# STM32MP23_CM33 register map
File version: 1.2
CPU: CM33 r0p1, little endian, MPU, FPU, vendor SysTick, 8 interrupt priority bits
Registers are 32-bit, read-write, reset 0x0 unless marked. A register's access mark holds for its fields unless they carry their own. Offsets are from the block's base; [hi:lo] are bit positions; {n}, {i} and the like mark numbered series.

## DSI (part 1 of 2) — DSI address block description
Base 0x48000000
Same registers: DSI_S 0x58000000
0x00 DSI_VR ro reset 0x3134312A — DSI Host version register
  [31:0] VERSION — Version of the DSI Host This read-only register contains the version of the DSI Host
0x04 DSI_CR — DSI Host control register
  [0] EN — Enable This bit configures the DSI Host in either power-up mode or to reset.
    0=DSI Host disabled (under reset); 1=DSI Host enabled
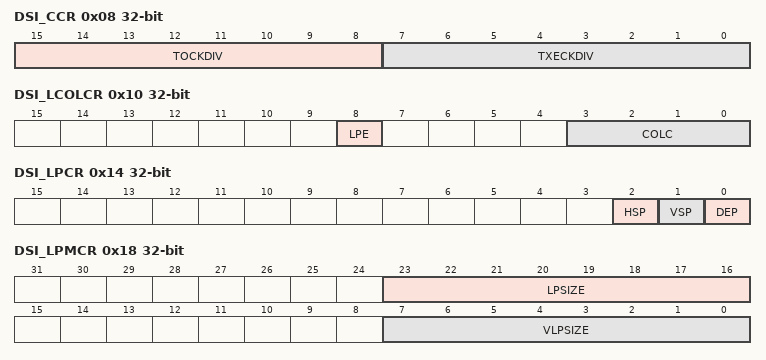
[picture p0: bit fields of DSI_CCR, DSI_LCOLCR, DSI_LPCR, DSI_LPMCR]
0x08 DSI_CCR — DSI Host clock control register
  [15:8] TOCKDIV — Timeout clock division This field indicates the division factor for the timeout clock used as the timing unit in the configuration of HS to LP and LP to HS transition error.
  [7:0] TXECKDIV — TX escape clock division This field indicates the division factor for the TX escape clock source (lanebyteclk). The values 0 and 1 stop the TX_ESC clock generation.
0x0C DSI_LVCIDR — DSI Host LTDC VCID register
  [1:0] VCID — Virtual channel ID These bits configure the virtual channel ID for the LTDC interface traffic.
0x10 DSI_LCOLCR — DSI Host LTDC color coding register
  [8] LPE — Loosely packet enable Enables the loosely packed variant to 18-bit configuration
    0=Loosely packet variant disabled; 1=Loosely packet variant enabled
  [3:0] COLC — Color coding This field configures the DPI color coding. Others: Reserved
    0=16-bit configuration 1; 1=16-bit configuration 2; 2=16-bit configuration 3; 3=18-bit configuration 1; 4=18-bit configuration 2; 5=24-bit
0x14 DSI_LPCR — DSI Host LTDC polarity configuration register
  [2] HSP — HSYNC polarity This bit configures the polarity of HSYNC pin.
    0=HSYNC pin active high (default); 1=VSYNC pin active low
  [1] VSP — VSYNC polarity This bit configures the polarity of VSYNC pin.
    0=Shutdown pin active high (default); 1=Shutdown pin active low
  [0] DEP — Data enable polarity This bit configures the polarity of data enable pin.
    0=Data enable pin active high (default); 1=Data enable pin active low
0x18 DSI_LPMCR — DSI Host low-power mode configuration register
  [23:16] LPSIZE — Largest packet size This field is used for the transmission of commands in low-power mode. It defines the size, in bytes, of the largest packet that can fit in a line during VSA, VBP and VFP regions.
  [7:0] VLPSIZE — VACT largest packet size This field is used for the transmission of commands in low-power mode. It defines the size, in bytes, of the largest packet that can fit in a line during VACT regions.
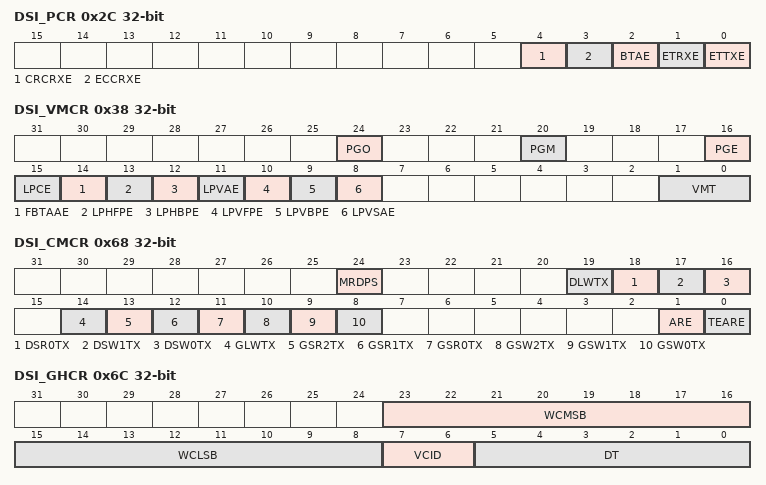
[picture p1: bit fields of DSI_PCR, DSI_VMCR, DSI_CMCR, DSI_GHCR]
0x2C DSI_PCR — DSI Host protocol configuration register
  [4] CRCRXE — CRC reception enable Enables the CRC reception and error reporting.
    0=CRC reception is disabled; 1=CRC reception is enabled
  [3] ECCRXE — ECC reception enable Enables the ECC reception, error correction and reporting.
    0=ECC reception is disabled; 1=ECC reception is enabled
  [2] BTAE — Bus-turn-around enable Enables the bus-turn-around (BTA) request.
    0=Bus-turn-around request is disabled; 1=Bus-turn-around request is enabled
  [1] ETRXE — EoTp reception enable Enables the EoTp reception.
    0=EoTp reception is disabled; 1=EoTp reception is enabled
  [0] ETTXE — EoTp transmission enable Enables the EoTP transmission.
    0=EoTp transmission is disabled; 1=EoTp transmission is enabled
0x30 DSI_GVCIDR ro — DSI Host generic VCID register
  [1:0] VCID — Virtual channel ID This field indicates the generic interface read-back virtual channel identification.
0x34 DSI_MCR reset 0x1 — DSI Host mode configuration register
  [0] CMDM — Command mode This bit configures the DSI Host in either video or command mode.
    0=DSI Host is configured in video mode; 1=DSI Host is configured in command mode
0x38 DSI_VMCR — DSI Host video mode configuration register
  [24] PGO — Pattern generator orientation This bit configures the color bar orientation.
    0=Vertical color bars; 1=Horizontal color bars
  [20] PGM — Pattern generator mode This bit configures the pattern generator mode.
    0=Color bars (horizontal or vertical); 1=BER pattern (vertical only)
  [16] PGE — Pattern generator enable Enables the video mode pattern generator.
    0=Pattern generator is disabled; 1=Pattern generator is enabled
  [15] LPCE — Low-power command enable Enables the command transmission only in low-power mode.
    0=Command transmission in low-power mode is disabled; 1=Command transmission in low-power mode is enabled
  [14] FBTAAE — Frame bus-turn-around acknowledge enable Enables the request for an acknowledge response at the end of a frame.
    0=Acknowledge response at the end of a frame is disabled; 1=Acknowledge response at the end of a frame is enabled
  [13] LPHFPE — Low-power horizontal front-porch enable Enables the return to low-power inside the horizontal front-porch (HFP) period when timing allows.
    0=Return to low-power inside the HFP period is disabled; 1=Return to low-power inside the HFP period is enabled
  [12] LPHBPE — Low-power horizontal back-porch enable Enables the return to low-power inside the horizontal back-porch (HBP) period when timing allows.
    0=Return to low-power inside the HBP period is disabled; 1=Return to low-power inside the HBP period is enabled
  [11] LPVAE — Low-power vertical active enable Enables to return to low-power inside the vertical active (VACT) period when timing allows.
    0=Return to low-power inside the VACT is disabled; 1=Return to low-power inside the VACT is enabled
  [10] LPVFPE — Low-power vertical front-porch enable Enables to return to low-power inside the vertical front-porch (VFP) period when timing allows.
    0=Return to low-power inside the VFP is disabled; 1=Return to low-power inside the VFP is enabled
  [9] LPVBPE — Low-power vertical back-porch enable Enables to return to low-power inside the vertical back-porch (VBP) period when timing allows.
    0=Return to low-power inside the VBP is disabled; 1=Return to low-power inside the VBP is enabled
  [8] LPVSAE — Low-power vertical sync active enable Enables to return to low-power inside the vertical sync time (VSA) period when timing allows.
    0=Return to low-power inside the VSA is disabled; 1=Return to low-power inside the VSA is enabled
  [1:0] VMT — Video mode type This field configures the video mode transmission type: 1x: Burst mode
    0=Non-burst with sync pulses; 1=Non-burst with sync events
0x3C DSI_VPCR — DSI Host video packet configuration register
  [13:0] VPSIZE — Video packet size This field configures the number of pixels in a single video packet. For 18-bit not loosely packed data types this number must be a multiple of 4. For YCbCr data types it must be a multiple of 2 as described in the DSI specification.
0x40 DSI_VCCR — DSI Host video chunks configuration register
  [12:0] NUMC — Number of chunks This register configures the number of chunks to be transmitted during a line period (a chunk consists of a video packet and a null packet). If set to 0 or 1, the video line is transmitted in a single packet. If set to 1, the packet is part of a chunk, so a null packet follows it if NPSIZE 0. Otherwise, multiple chunks are used to transmit each video line.
0x44 DSI_VNPCR — DSI Host video null packet configuration register
  [12:0] NPSIZE — Null packet size This field configures the number of bytes inside a null packet. Setting to 0 disables the null packets.
0x48 DSI_VHSACR — DSI Host video HSA configuration register
  [11:0] HSA — Horizontal synchronism active duration This fields configures the horizontal synchronism active period in lane byte clock cycles.
0x4C DSI_VHBPCR — DSI Host video HBP configuration register
  [11:0] HBP — Horizontal back-porch duration This fields configures the horizontal back-porch period in lane byte clock cycles.
0x50 DSI_VLCR — DSI Host video line configuration register
  [14:0] HLINE — Horizontal line duration This fields configures the total of the horizontal line period (HSA+HBP+HACT+HFP) counted in lane byte clock cycles.
0x54 DSI_VVSACR — DSI Host video VSA configuration register
  [9:0] VSA — Vertical synchronism active duration This fields configures the vertical synchronism active period measured in number of horizontal lines.
0x58 DSI_VVBPCR — DSI Host video VBP configuration register
  [9:0] VBP — Vertical back-porch duration This fields configures the vertical back-porch period measured in number of horizontal lines.
0x5C DSI_VVFPCR — DSI Host video VFP configuration register
  [9:0] VFP — Vertical front-porch duration This fields configures the vertical front-porch period measured in number of horizontal lines.
0x60 DSI_VVACR — DSI Host video VA configuration register
  [13:0] VA — Vertical active duration This fields configures the vertical active period measured in number of horizontal lines.
0x64 DSI_LCCR — DSI Host LTDC command configuration register
  [15:0] CMDSIZE — Command size This field configures the maximum allowed size for an LTDC write memory command, measured in pixels. Automatic partitioning of data obtained from LTDC is permanently enabled.
0x68 DSI_CMCR — DSI Host command mode configuration register
  [24] MRDPS — Maximum read packet size This bit configures the maximum read packet size command transmission type:
    0=High-speed; 1=Low-power
  [19] DLWTX — DCS long write transmission This bit configures the DCS long write packet command transmission type:
    0=High-speed; 1=Low-power
  [18] DSR0TX — DCS short read zero parameter transmission This bit configures the DCS short read packet with zero parameter command transmission type:
    0=High-speed; 1=Low-power
  [17] DSW1TX — DCS short read one parameter transmission This bit configures the DCS short read packet with one parameter command transmission type:
    0=High-speed; 1=Low-power
  [16] DSW0TX — DCS short write zero parameter transmission This bit configures the DCS short write packet with zero parameter command transmission type:
    0=High-speed; 1=Low-power
  [14] GLWTX — Generic long write transmission This bit configures the generic long write packet command transmission type :
    0=High-speed; 1=Low-power
  [13] GSR2TX — Generic short read two parameters transmission This bit configures the generic short read packet with two parameters command transmission type:
    0=High-speed; 1=Low-power
  [12] GSR1TX — Generic short read one parameters transmission This bit configures the generic short read packet with one parameters command transmission type:
    0=High-speed; 1=Low-power
  [11] GSR0TX — Generic short read zero parameters transmission This bit configures the generic short read packet with zero parameters command transmission type:
    0=High-speed; 1=Low-power
  [10] GSW2TX — Generic short write two parameters transmission This bit configures the generic short write packet with two parameters command transmission type:
    0=High-speed; 1=Low-power
  [9] GSW1TX — Generic short write one parameters transmission This bit configures the generic short write packet with one parameters command transmission type:
    0=High-speed; 1=Low-power
  [8] GSW0TX — Generic short write zero parameters transmission This bit configures the generic short write packet with zero parameters command transmission type:
    0=High-speed; 1=Low-power
  [1] ARE — Acknowledge request enable Enables the acknowledge request after each packet transmission:
    0=Acknowledge request is disabled; 1=Acknowledge request is enabled
  [0] TEARE — Tearing effect acknowledge request enable Enables the tearing effect acknowledge request:
    0=Tearing effect acknowledge request is disabled; 1=Tearing effect acknowledge request is enabled
0x6C DSI_GHCR — DSI Host generic header configuration register
  [23:16] WCMSB — WordCount MSB This field configures the most significant byte of the header packet’s word count for long packets, or data 1 for short packets.
  [15:8] WCLSB — WordCount LSB This field configures the less significant byte of the header packet word count for long packets, or data 0 for short packets.
  [7:6] VCID — Channel This field configures the virtual channel ID of the header packet.
  [5:0] DT — Type This field configures the packet data type of the header packet.
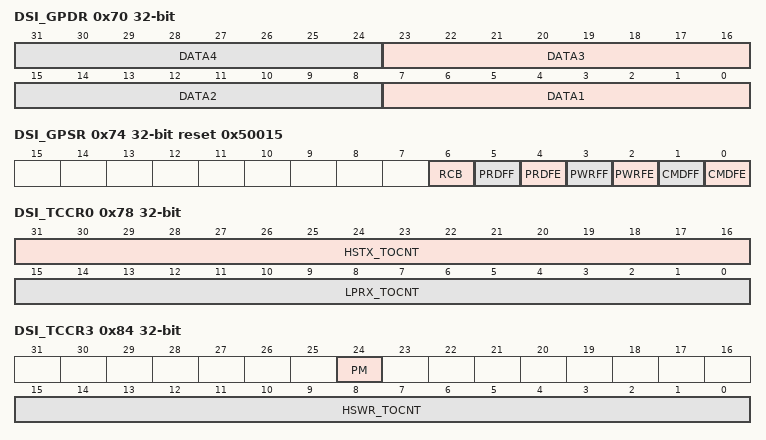
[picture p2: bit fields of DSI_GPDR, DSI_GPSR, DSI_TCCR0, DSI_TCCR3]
0x70 DSI_GPDR — DSI Host generic payload data register
  [8n-1:8n-8] DATA{n} (n=1..4) — Payload byte {n} This field indicates byte {n} of the packet payload.
0x74 DSI_GPSR ro reset 0x50015 — DSI Host generic packet status register
  [6] RCB — Read command busy This bit is set when a read command is issued and cleared when the entire response is stored in the FIFO:
    0=No read command ongoing; 1=Read command ongoing
  [5] PRDFF — Payload read FIFO full Indicates the full status of the generic read payload FIFO:
    0=Read payload FIFO not full; 1=Read payload FIFO full
  [4] PRDFE — Payload read FIFO empty Indicates the empty status of the generic read payload FIFO:
    0=Read payload FIFO not empty; 1=Read payload FIFO empty
  [3] PWRFF — Payload write FIFO full Indicates the full status of the generic write payload FIFO:
    0=Write payload FIFO not full; 1=Write payload FIFO full
  [2] PWRFE — Payload write FIFO empty Indicates the empty status of the generic write payload FIFO:
    0=Write payload FIFO not empty; 1=Write payload FIFO empty
  [1] CMDFF — Command FIFO full Indicates the full status of the generic command FIFO:
    0=Write payload FIFO not full; 1=Write payload FIFO full
  [0] CMDFE — Command FIFO empty Indicates the empty status of the generic command FIFO:
    0=Write payload FIFO not empty; 1=Write payload FIFO empty
0x78 DSI_TCCR0 — DSI Host timeout counter configuration register 0
  [31:16] HSTX_TOCNT — High-speed transmission timeout counter This field configures the timeout counter that triggers a high-speed transmission timeout contention detection (measured in TOCKDIV cycles). If using the non-burst mode and there is no enough time to switch from high-speed to low-power and back in the period from one line data finishing to the next line sync start, the DSI link returns the low-power state once per frame, then configure the TOCKDIV and HSTX_TOCNT to be in accordance with: HSTX_TOCNT * lanebyteclkperiod * TOCKDIV ≥ the time of one FRAME data transmission * (1 + 10%) In burst mode, RGB pixel packets are time-compressed, leaving more time during a scan line. Therefore, if in burst mode and there is enough time to switch from high-speed to low-power and back in the period from one line data finishing to the next line sync start, the DSI link can return low-power mode and back in this time interval to save power. For this, configure the TOCKDIV and HSTX_TOCNT to be in accordance with: HSTX_TOCNT * lanebyteclkperiod * TOCKDIV ≥ the time of one LINE data transmission * (1 + 10%)
  [15:0] LPRX_TOCNT — Low-power reception timeout counter This field configures the timeout counter that triggers a low-power reception timeout contention detection (measured in TOCKDIV cycles).
0x7C DSI_TCCR1 — DSI Host timeout counter configuration register 1
  [15:0] HSRD_TOCNT — High-speed read timeout counter This field sets a period for which the DSI Host keeps the link still, after sending a high-speed read operation. This period is measured in cycles of lanebyteclk. The counting starts when the D-PHY enters the Stop state and causes no interrupts.
0x80 DSI_TCCR2 — DSI Host timeout counter configuration register 2
  [15:0] LPRD_TOCNT — Low-power read timeout counter This field sets a period for which the DSI Host keeps the link still, after sending a low-power read operation. This period is measured in cycles of lanebyteclk. The counting starts when the D-PHY enters the Stop state and causes no interrupts.
0x84 DSI_TCCR3 — DSI Host timeout counter configuration register 3
  [24] PM — Presp mode When set to 1, this bit ensures that the peripheral response timeout caused by HSWR_TOCNT is used only once per LTDC frame in command mode, when both the following conditions are met: dpivsync_edpiwms has risen and fallen. Packets originated from LTDC in command mode have been transmitted and its FIFO is empty again. In this scenario no non-LTDC command requests are sent to the D-PHY, even if there is traffic from generic interface ready to be sent, making it return to stop state. When it does so, PRESP_TO counter is activated and only when it finishes does the controller send any other traffic that is ready.
  [15:0] HSWR_TOCNT — High-speed write timeout counter This field sets a period for which the DSI Host keeps the link inactive after sending a high-speed write operation. This period is measured in cycles of lanebyteclk. The counting starts when the D-PHY enters the Stop state and causes no interrupts.
0x88 DSI_TCCR4 — DSI Host timeout counter configuration register 4
  [15:0] LPWR_TOCNT — Low-power write timeout counter This field sets a period for which the DSI Host keeps the link still, after sending a low-power write operation. This period is measured in cycles of lanebyteclk. The counting starts when the D-PHY enters the Stop state and causes no interrupts.
0x8C DSI_TCCR5 — DSI Host timeout counter configuration register 5
  [15:0] BTA_TOCNT — Bus-turn-around timeout counter This field sets a period for which the DSI Host keeps the link still, after completing a bus-turn-around. This period is measured in cycles of lanebyteclk. The counting starts when the D-PHY enters the Stop state and causes no interrupts.
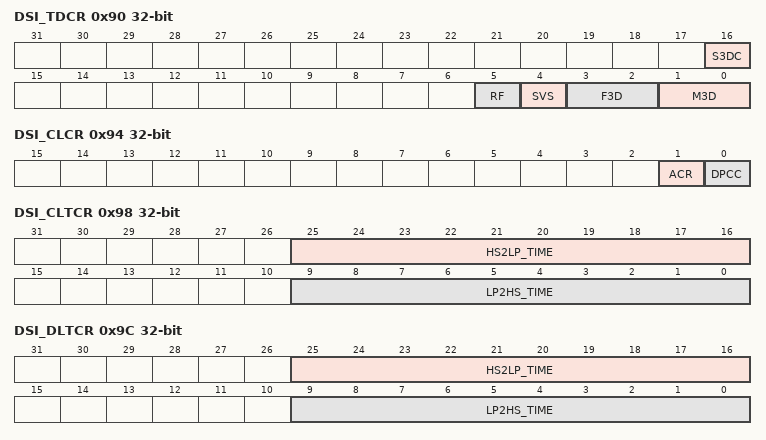
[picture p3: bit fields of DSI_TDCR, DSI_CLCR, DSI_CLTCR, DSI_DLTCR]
0x90 DSI_TDCR — DSI Host 3D configuration register
  [16] S3DC — Send 3D control When set, causes the next VSS packet to include 3D control payload in every VSS packet.
  [5] RF — Right first This bit defines the left or right order:
    0=Left eye data is sent first, and then the right eye data is sent; 1=Right eye data is sent first, and then the left eye data is sent
  [4] SVS — Second VSYNC This field defines whether there is a second VSYNC pulse between left and right images, when 3D image format is frame-based:
    0=No sync pulses between left and right data; 1=Sync pulse (HSYNC, VSYNC, blanking) between left and right data
  [3:2] F3D — 3D format This field defines the 3D image format:
    0=Line (alternating lines of left and right data); 1=Frame (alternating frames of left and right data); 2=Pixel (alternating pixels of left and right data)
  [1:0] M3D — 3D mode This field defines the 3D mode on/off and display orientation:
    0=3D mode off (2D mode on); 1=3D mode on, portrait orientation; 2=3D mode on, landscape orientation
0x94 DSI_CLCR — DSI Host clock lane configuration register
  [1] ACR — Automatic clock lane control Enables the automatic mechanism to stop providing clock in the clock lane when time allows.
    0=Automatic clock lane control disabled; 1=Automatic clock lane control enabled
  [0] DPCC — D-PHY clock control This bit controls the D-PHY clock state:
    0=Clock lane is in low-power mode; 1=Clock lane runs in high-speed mode
0x98 DSI_CLTCR — DSI Host clock lane timer configuration register
  [25:16] HS2LP_TIME — High-speed to low-power time This field configures the maximum time that the D-PHY clock lane takes to go from high-speed to low-power transmission measured in lane byte clock cycles.
  [9:0] LP2HS_TIME — Low-power to high-speed time This field configures the maximum time that the D-PHY clock lane takes to go from low-power to high-speed transmission measured in lane byte clock cycles.
0x9C DSI_DLTCR — DSI Host data lane timer configuration register
  [25:16] HS2LP_TIME — High-speed to low-power time This field configures the maximum time that the D-PHY data lanes take to go from high-speed to low-power transmission measured in lane byte clock cycles.
  [9:0] LP2HS_TIME — Low-power to high-speed time This field configures the maximum time that the D-PHY data lanes take to go from low-power to high-speed transmission measured in lane byte clock cycles.
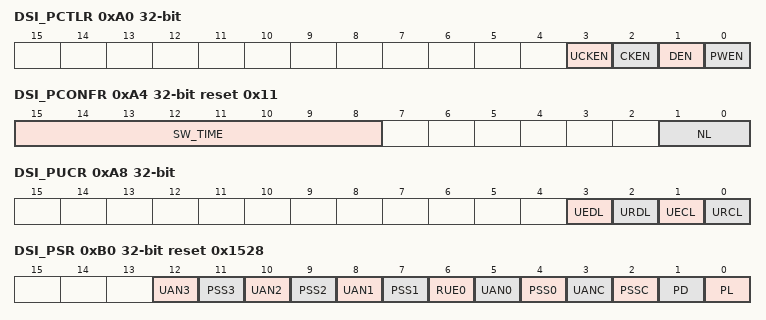
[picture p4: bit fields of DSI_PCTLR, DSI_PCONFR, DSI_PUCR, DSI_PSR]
0xA0 DSI_PCTLR — DSI Host PHY control register
  [3] UCKEN — ULPS clock enable Enables the D-PHY PLL clock when in ULPS mode:
    0=D-PHY clock lane module is disabled when in ULPS mode; 1=D-PHY clock lane module is enabled when in ULPS mode
  [2] CKEN — Clock enable Enables the D-PHY clock lane module:
    0=D-PHY clock lane module is disabled; 1=D-PHY clock lane module is enabled
  [1] DEN — Digital enable When set to 0, this bit places the digital section of the D-PHY in the reset state
    0=The digital section of the D-PHY is in the reset state; 1=The digital section of the D-PHY is enabled
  [0] PWEN — Power enable When set to 0, this bit places the complete D-PHY in the power-down state
    0=The complete D-PHY is in the power-down state; 1=The complete D-PHY is enabled
0xA4 DSI_PCONFR reset 0x11 — DSI Host PHY configuration register
  [15:8] SW_TIME — Stop wait time This field configures the minimum wait period to request a high-speed transmission after the Stop state.
  [1:0] NL — Number of lanes This field configures the number of active data lanes:
    0=One data lane (0); 1=Two data lanes (0 and 1); 2=Three data lanes (0, 1 and 2); 3=Four data lanes (0, 1, 2 and 3) - Reset value
0xA8 DSI_PUCR — DSI Host PHY ULPS control register
  [3] UEDL — ULPS exit on data lane ULPS mode exit on all active data lanes.
    0=No exit request; 1=Exit ULPS mode on all active data lane URDL
  [2] URDL — ULPS request on data lane ULPS mode request on all active data lanes.
    0=No ULPS request; 1=Request ULPS mode on all active data lane UECL
  [1] UECL — ULPS exit on clock lane ULPS mode exit on clock lane.
    0=No exit request; 1=Exit ULPS mode on clock lane
  [0] URCL — ULPS request on clock lane ULPS mode request on clock lane.
    0=No ULPS request; 1=Request ULPS mode on clock lane
0xAC DSI_PTTCR — DSI Host PHY TX triggers configuration register
  [3:0] TX_TRIG — Transmission trigger Escape mode transmit trigger 0-3. Only one bit of TX_TRIG is asserted at any given time.
0xB0 DSI_PSR ro reset 0x1528 — DSI Host PHY status register
  [12] UAN3 — ULPS active not lane 3 Indicates the status of ulpsactivenot1lane D-PHY signal.
  [11] PSS3 — PHY stop state lane 3 Indicates the status of phystopstate1lane D-PHY signal.
  [10] UAN2 — ULPS active not lane 2 Indicates the status of ulpsactivenot1lane D-PHY signal.
  [9] PSS2 — PHY stop state lane 2 Indicates the status of phystopstate1lane D-PHY signal.
  [8] UAN1 — ULPS active not lane 1 Indicates the status of ulpsactivenot1lane D-PHY signal.
  [7] PSS1 — PHY stop state lane 1 Indicates the status of phystopstate1lane D-PHY signal.
  [6] RUE0 — RX ULPS escape lane 0 Indicates the status of rxulpsesc0lane D-PHY signal.
  [5] UAN0 — ULPS active not lane 0 Indicates the status of ulpsactivenot0lane D-PHY signal.
  [4] PSS0 — PHY stop state lane 0 Indicates the status of phystopstate0lane D-PHY signal.
  [3] UANC — ULPS active not clock lane Indicates the status of ulpsactivenotclklane D-PHY signal.
  [2] PSSC — PHY stop state clock lane Indicates the status of phystopstateclklane D-PHY signal.
  [1] PD — PHY direction Indicates the status of phydirection D-PHY signal.
  [0] PL — PHY direction Indicates the status of rxulpsesc0lane D-PHY signal.
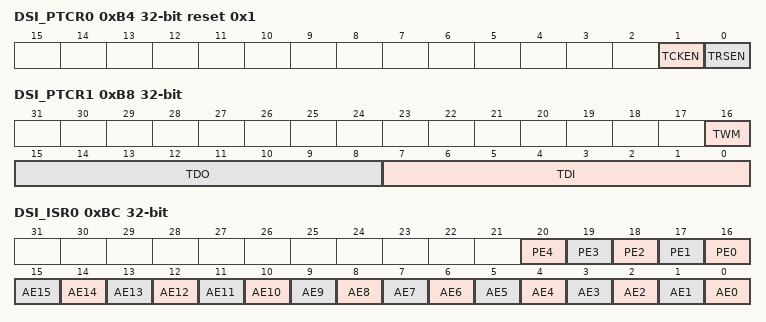
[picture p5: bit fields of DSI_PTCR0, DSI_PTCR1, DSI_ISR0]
0xB4 DSI_PTCR0 ro reset 0x1 — DSI Host PHY test control register 0
  [1] TCKEN — Test-interface clock enable for the TDI bus into the PHY:
    0=D-PHY test clock is disabled; 1=D-PHY test clock is enabled
  [0] TRSEN — Test-interface reset enable for the TDI bus into the D-PHY:
    0=D-PHY test interface is available; 1=D-PHY test interface is reset (reset value)
0xB8 DSI_PTCR1 — DSI Host PHY test control register 1
  [16] TWM — Test write mode, selects the test write access performed to the D-PHY:
    0=the data write operation is set on the rising edge of the test clock signal; 1=the address write operation is set on the falling edge of the test clock signal
  [15:8] TDO — Test data out This field configures the TESTDOUT test bus sent to the D-PHY.
  [7:0] TDI — Test data in This field configures the TESTDIN bus returning from the D-PHY.
0xBC DSI_ISR0 ro — DSI Host interrupt and status register 0
  [20] PE4 — PHY error 4 Indicates the LP1 contention error ErrContentionLP1 from lane 0.
  [19] PE3 — PHY error 3 Indicates the LP0 contention error ErrContentionLP0 from lane 0.
  [18] PE2 — PHY error 2 Indicates the ErrControl error from lane 0.
  [17] PE1 — PHY error 1 Indicates the ErrSyncEsc low-power transmission synchronization error from lane 0.
  [16] PE0 — PHY error 0 Indicates the ErrEsc escape entry error from lane 0.
  [15] AE15 — Acknowledge error 15 Retrieves the DSI protocol violation from the acknowledge error report.
  [14] AE14 — Acknowledge error 14 Retrieves the reserved (specific to the device) from the acknowledge error report.
  [13] AE13 — Acknowledge error 13 Retrieves the invalid transmission length from the acknowledge error report.
  [12] AE12 — Acknowledge error 12 Retrieves the DSI VC ID Invalid from the acknowledge error report.
  [11] AE11 — Acknowledge error 11 Retrieves the not recognized DSI data type from the acknowledge error report.
  [10] AE10 — Acknowledge error 10 Retrieves the checksum error (long packet only) from the acknowledge error report.
  [9] AE9 — Acknowledge error 9 Retrieves the ECC error, multi-bit (detected, not corrected) from the acknowledge error report.
  [8] AE8 — Acknowledge error 8 Retrieves the ECC error, single-bit (detected and corrected) from the acknowledge error report.
  [7] AE7 — Acknowledge error 7 Retrieves the reserved (specific to the device) from the acknowledge error report.
  [6] AE6 — Acknowledge error 6 Retrieves the false control error from the acknowledge error report.
  [5] AE5 — Acknowledge error 5 Retrieves the peripheral timeout error from the acknowledge error report.
  [4] AE4 — Acknowledge error 4 Retrieves the LP transmit sync error from the acknowledge error report.
  [3] AE3 — Acknowledge error 3 Retrieves the escape mode entry command error from the acknowledge error report.
  [2] AE2 — Acknowledge error 2 Retrieves the EoT sync error from the acknowledge error report.
  [1] AE1 — Acknowledge error 1 Retrieves the SoT sync error from the acknowledge error report.
  [0] AE0 — Acknowledge error 0 Retrieves the SoT error from the acknowledge error report.
